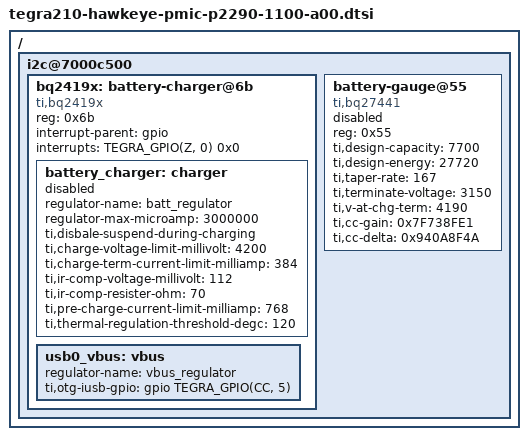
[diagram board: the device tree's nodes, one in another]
/*
 * Copyright (c) 2014, NVIDIA CORPORATION.  All rights reserved.
 *
 * This program is free software; you can redistribute it and/or modify
 * it under the terms of the GNU General Public License as published by
 * the Free Software Foundation; either version 2 of the License, or
 * (at your option) any later version.
 *
 * This program is distributed in the hope that it will be useful, but WITHOUT
 * ANY WARRANTY; without even the implied warranty of MERCHANTABILITY or
 * FITNESS FOR A PARTICULAR PURPOSE.  See the GNU General Public License for
 * more details.
 *
 * You should have received a copy of the GNU General Public License
 * along with this program.  If not, see <http://www.gnu.org/licenses/>.
 */

#include <dt-bindings/mfd/max77620.h>
#include <dt-bindings/regulator/regulator.h>
#include <dt-bindings/gpio/tegra-gpio.h>
#include <dt-bindings/thermal/thermal.h>

/ {
	i2c@7000c500 {
		bq2419x: battery-charger@6b {
			compatible = "ti,bq2419x";
			reg = <0x6b>;

			interrupt-parent = <&gpio>;
			interrupts = <TEGRA_GPIO(Z, 0) 0x0>;
			#extcon-cells = <1>;

			#thermal-sensor-cells = <0>;

			battery_charger: charger {
				status = "disabled";
				regulator-name = "batt_regulator";
				regulator-max-microamp = <3000000>;
				ti,disbale-suspend-during-charging;
				ti,charge-voltage-limit-millivolt = <4200>;
				ti,charge-term-current-limit-milliamp = <384>;
				ti,ir-comp-voltage-millivolt = <112>;
				ti,ir-comp-resister-ohm = <70>;
				ti,pre-charge-current-limit-milliamp = <768>;
				ti,thermal-regulation-threshold-degc = <120>;
			};

			usb0_vbus: vbus {
				regulator-name = "vbus_regulator";
				ti,otg-iusb-gpio = <&gpio TEGRA_GPIO(CC, 5) 0>;
			};
		};

		battery-gauge@55 {
			status = "disabled";
			compatible = "ti,bq27441";
			reg = <0x55>;
			ti,design-capacity = <7700>;
			ti,design-energy = <27720>;
			ti,taper-rate = <167>;
			ti,terminate-voltage = <3150>;
			ti,v-at-chg-term = <4190>;
			ti,cc-gain = <0x7F738FE1>;
			ti,cc-delta = <0x940A8F4A>;
		};
	};
};
